# Polarfire SoC register map
Vendor: Microchip; File version: 1.0
CPU: Microchip PolarFire SoC 1.0, little endian
Registers are 32-bit, read-write, reset 0x0 unless marked. A register's access mark holds for its fields unless they carry their own. Offsets are from the block's base; [hi:lo] are bit positions; lines under a group give offsets from that group; {n}, {i} and the like mark numbered series; 'fields as' and 'values as' point back to an identical list.

## USB — MSS USB 2.0 OTG High-Speed Controller
Base 0x20201000
0x00 FADDR 8-bit reset not defined — Function Address Register (peripheral mode)
  [6:0] FUNC_ADDR — USB function address (0–127)
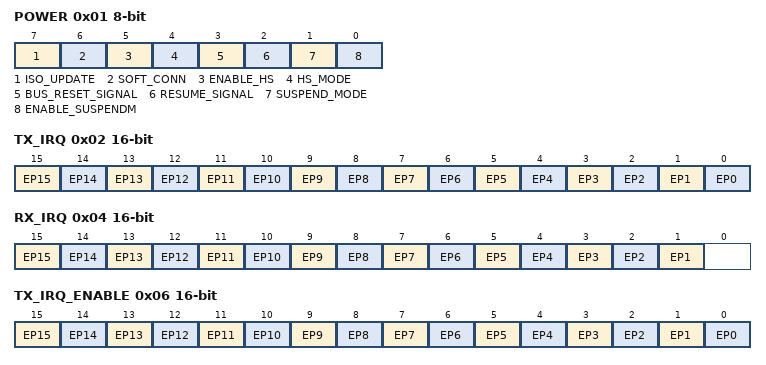
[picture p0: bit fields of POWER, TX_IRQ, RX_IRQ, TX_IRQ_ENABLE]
0x01 POWER 8-bit reset not defined — Power Management and High-Speed Control Register
  [7] ISO_UPDATE — Isochronous update: wait for SOF before sending (peripheral)
  [6] SOFT_CONN — Soft connect / disconnect control (peripheral mode)
  [5] ENABLE_HS — Enable high-speed negotiation during reset
  [4] HS_MODE ro — High-speed mode negotiated and active (read-only)
  [3] BUS_RESET_SIGNAL — USB bus reset signalling active (read-only in device mode)
  [2] RESUME_SIGNAL — Drive resume signalling on the bus
  [1] SUSPEND_MODE ro — USB suspend mode active (read-only)
  [0] ENABLE_SUSPENDM — Enable SuspendM signal output
0x02 TX_IRQ 16-bit ro reset not defined — TX Endpoint Interrupt Status Register (read-clears)
  [n] EP{n} (n=1..15) — TX EP{n} interrupt pending
  [0] EP0 — EP0 interrupt pending
0x04 RX_IRQ 16-bit ro reset not defined — RX Endpoint Interrupt Status Register (read-clears; bit 0 unused)
  [n] EP{n} (n=1..15) — RX EP{n} interrupt pending
0x06 TX_IRQ_ENABLE 16-bit reset not defined — TX Endpoint Interrupt Enable Register
  [n] EP{n} (n=1..15) — TX EP{n} interrupt enable
  [0] EP0 — EP0 / control endpoint interrupt enable
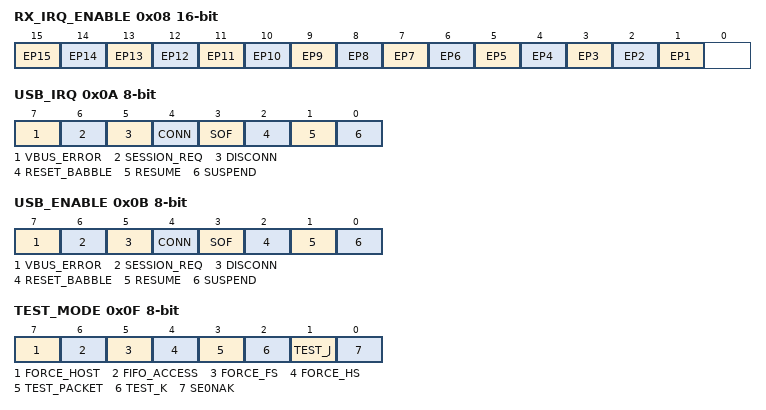
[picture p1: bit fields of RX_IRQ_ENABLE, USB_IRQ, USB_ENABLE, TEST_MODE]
0x08 RX_IRQ_ENABLE 16-bit reset not defined — RX Endpoint Interrupt Enable Register
  [n] EP{n} (n=1..15) — RX EP{n} interrupt enable
0x0A USB_IRQ 8-bit ro reset not defined — USB Common Interrupt Status Register
  [7] VBUS_ERROR — VBUS error (OTG)
  [6] SESSION_REQ — Session-request protocol event (OTG)
  [5] DISCONN — Device disconnected
  [4] CONN — Device connected (host mode)
  [3] SOF — Start-of-Frame token received / generated
  [2] RESET_BABBLE — Bus reset (device) or babble (host) detected
  [1] RESUME — Resume signalling detected
  [0] SUSPEND — Suspend condition detected
0x0B USB_ENABLE 8-bit reset not defined — USB Common Interrupt Enable Register
  [7] VBUS_ERROR — VBUS error interrupt enable
  [6] SESSION_REQ — Session-request interrupt enable
  [5] DISCONN — Disconnect interrupt enable
  [4] CONN — Connect interrupt enable
  [3] SOF — SOF interrupt enable
  [2] RESET_BABBLE — Reset/babble interrupt enable
  [1] RESUME — Resume interrupt enable
  [0] SUSPEND — Suspend interrupt enable
0x0C FRAME 16-bit ro reset not defined — USB Frame Number Register (read-only)
  [10:0] FRAME_NUM — Current USB SOF frame number (0–2047)
0x0E INDEX 8-bit reset not defined — Endpoint Index Register — selects which endpoint CSRs appear at 0x010–0x01F
  [3:0] ENDPOINT_INDEX — Active endpoint number (0–15) for indexed CSR window
0x0F TEST_MODE 8-bit reset not defined — USB Test Mode Control Register
  [7] FORCE_HOST — Force host mode
  [6] FIFO_ACCESS — Enable FIFO access mode (self-clearing)
  [5] FORCE_FS — Force full-speed operation
  [4] FORCE_HS — Force high-speed operation
  [3] TEST_PACKET — Transmit test packet
  [2] TEST_K — Force HS Test_K state
  [1] TEST_J — Force HS Test_J state
  [0] SE0NAK — Force SE0/NAK test
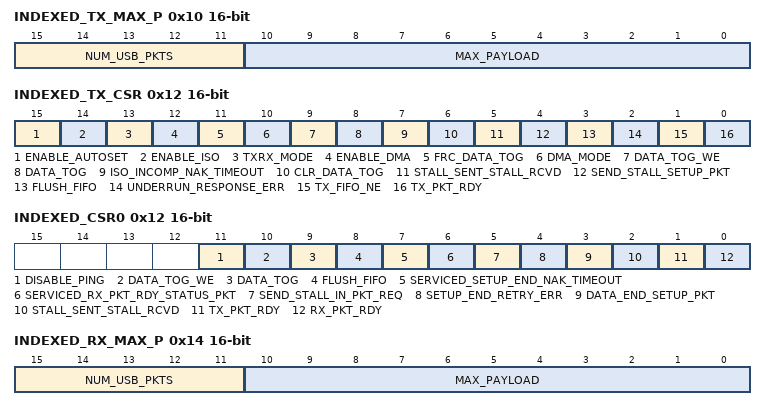
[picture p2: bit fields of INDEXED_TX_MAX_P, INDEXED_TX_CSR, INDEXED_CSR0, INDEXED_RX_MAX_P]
0x10 INDEXED_TX_MAX_P 16-bit reset not defined — Indexed TX Maximum Packet Size (endpoint selected by INDEX)
  [15:11] NUM_USB_PKTS — High-bandwidth packets per micro-frame minus 1 (bits[15:11])
  [10:0] MAX_PAYLOAD — Maximum TX packet payload in bytes (bits[10:0])
0x12 INDEXED_TX_CSR 16-bit reset not defined — Indexed TX Control/Status Register — EPN view (N>0). Upper byte (TxCSRH) carries DMA and mode control. Bit semantics differ between device and host mode.
  [15] ENABLE_AUTOSET — Auto-set TxPktRdy when FIFO full
  [14] ENABLE_ISO — Isochronous mode enable (device only)
  [13] TXRX_MODE — Direction mode: 1=TX only when endpoint is bidirectional
  [12] ENABLE_DMA — Enable DMA request for this TX endpoint
  [11] FRC_DATA_TOG — Force data toggle (used for bulk transactions)
  [10] DMA_MODE — DMA request mode: 0=mode0, 1=mode1
  [9] DATA_TOG_WE — Enable write to DATA_TOG bit (host only, self-clearing)
  [8] DATA_TOG ro — Current TX data toggle value (host only, read-only)
  [7] ISO_INCOMP_NAK_TIMEOUT — Incomplete ISO TX (device) / NAK timeout (host)
  [6] CLR_DATA_TOG — Reset TX data toggle to DATA0
  [5] STALL_SENT_STALL_RCVD — STALL handshake sent (device) / STALL received (host)
  [4] SEND_STALL_SETUP_PKT — Issue STALL handshake (device) / send SETUP token (host)
  [3] FLUSH_FIFO — Flush TX FIFO (self-clearing)
  [2] UNDERRUN_RESPONSE_ERR — Underrun error (device) / no response error (host)
  [1] TX_FIFO_NE ro — TX FIFO not empty (read-only)
  [0] TX_PKT_RDY — Set to indicate TX FIFO loaded; cleared by hardware after transmission
0x12 INDEXED_CSR0 16-bit reset not defined (alternate view of INDEXED_TX_CSR) — Indexed EP0 Control/Status Register — EP0 view only (INDEX=0). Overlaps INDEXED_TX_CSR; bit definitions differ completely.
  [11] DISABLE_PING — Disable PING token generation (host only)
  [10] DATA_TOG_WE — Enable write to DATA_TOG (host only, self-clearing)
  [9] DATA_TOG — Data toggle value (host only)
  [8] FLUSH_FIFO — Flush EP0 FIFO (self-clearing)
  [7] SERVICED_SETUP_END_NAK_TIMEOUT — ServicedSetupEnd (device) / NAK timeout (host)
  [6] SERVICED_RX_PKT_RDY_STATUS_PKT — ServicedRxPktRdy (device) / status packet (host)
  [5] SEND_STALL_IN_PKT_REQ — Issue STALL (device) / IN packet request (host)
  [4] SETUP_END_RETRY_ERR ro — Setup end condition (device, read-only) / retry error (host)
  [3] DATA_END_SETUP_PKT — Signal data end (device) / SETUP packet (host)
  [2] STALL_SENT_STALL_RCVD ro — STALL sent (device) / STALL received (host)
  [1] TX_PKT_RDY — Data packet loaded in EP0 TX FIFO (device/host)
  [0] RX_PKT_RDY ro — Data packet received in EP0 RX FIFO (device) / RX ready (host)
0x14 INDEXED_RX_MAX_P 16-bit reset not defined — Indexed RX Maximum Packet Size (endpoint selected by INDEX)
  [15:11] NUM_USB_PKTS — High-bandwidth packets per micro-frame minus 1 (bits[15:11])
  [10:0] MAX_PAYLOAD — Maximum RX packet payload in bytes (bits[10:0])
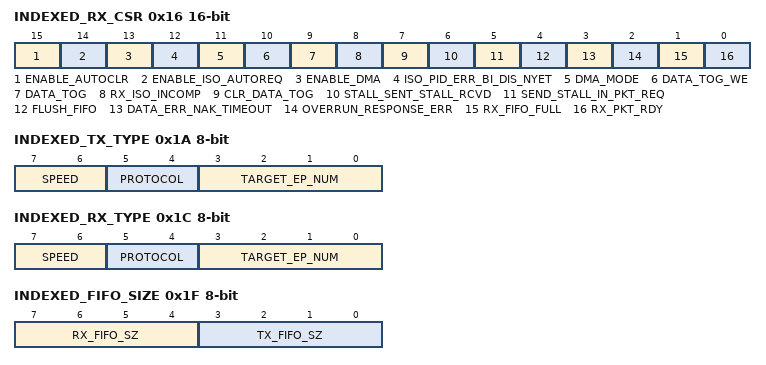
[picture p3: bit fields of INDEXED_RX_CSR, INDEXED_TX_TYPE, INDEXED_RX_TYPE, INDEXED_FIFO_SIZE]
0x16 INDEXED_RX_CSR 16-bit reset not defined — Indexed RX Control/Status Register — EPN view (N>0). Upper byte (RxCSRH) carries DMA, ISO and mode bits. Bit semantics differ between device and host mode.
  [15] ENABLE_AUTOCLR — Auto-clear RxPktRdy when FIFO drained
  [14] ENABLE_ISO_AUTOREQ — ISO mode enable (device) / auto-request IN (host)
  [13] ENABLE_DMA — Enable DMA request for this RX endpoint
  [12] ISO_PID_ERR_BI_DIS_NYET — ISO PID error (device) / disable NYET handshake (host)
  [11] DMA_MODE — DMA request mode: 0=mode0, 1=mode1
  [10] DATA_TOG_WE — Enable write to DATA_TOG (host only)
  [9] DATA_TOG ro — Current RX data toggle (host only, read-only)
  [8] RX_ISO_INCOMP ro — Incomplete ISO RX in this frame
  [7] CLR_DATA_TOG — Reset RX data toggle to DATA0
  [6] STALL_SENT_STALL_RCVD — STALL sent (device) / STALL received (host)
  [5] SEND_STALL_IN_PKT_REQ — Issue STALL (device) / IN packet request (host)
  [4] FLUSH_FIFO — Flush RX FIFO (self-clearing)
  [3] DATA_ERR_NAK_TIMEOUT — Data CRC/bit-stuff error (device) / NAK timeout (host)
  [2] OVERRUN_RESPONSE_ERR — Overrun (device) / no response error (host)
  [1] RX_FIFO_FULL ro — RX FIFO full (read-only)
  [0] RX_PKT_RDY ro — Data packet available in RX FIFO (cleared by software)
0x18 INDEXED_RX_COUNT 16-bit ro reset not defined — Indexed RX Byte Count Register (COUNT0 for EP0; read-only)
  [13:0] COUNT — Number of bytes in RX FIFO (EP0: max 64 / EPN: up to 16383)
0x1A INDEXED_TX_TYPE 8-bit reset not defined — Indexed TX Type Register — target EP, protocol, speed (host mode; TYPE0 for EP0)
  [7:6] SPEED — Target device speed: 00=same as bus, 01=High, 10=Full, 11=Low
    0=SAME_AS_BUS; 1=HIGH_SPEED; 2=FULL_SPEED; 3=LOW_SPEED
  [5:4] PROTOCOL — Transfer type: 00=Control, 01=Isoch, 10=Bulk, 11=Interrupt
    0=CONTROL; 1=ISOCHRONOUS; 2=BULK; 3=INTERRUPT
  [3:0] TARGET_EP_NUM — Target endpoint number on the remote device
0x1B INDEXED_TX_INTERVAL 8-bit reset not defined — Indexed TX Polling Interval / NAK Limit (host; NAK_LIMIT0 for EP0)
  [7:0] INTERVAL — Polling interval (interrupt/ISO) or NAK retry limit (bulk/control)
0x1C INDEXED_RX_TYPE 8-bit reset not defined — Indexed RX Type Register — target EP, protocol, speed (host mode)
  fields as INDEXED_TX_TYPE
0x1D INDEXED_RX_INTERVAL 8-bit reset not defined — Indexed RX Polling Interval / NAK Limit (host mode)
  [7:0] INTERVAL — Polling interval or NAK retry limit
0x1F INDEXED_FIFO_SIZE 8-bit ro reset not defined — Indexed FIFO Size / Config Data Register (read-only)
  [7:4] RX_FIFO_SZ — RX FIFO size encoding [7:4]
  [3:0] TX_FIFO_SZ — TX FIFO size encoding [3:0]
{0x20+4i} FIFO[{i}] (i=0..15) reset not defined — Endpoint {i} FIFO Data Port (32-bit access; 8- and 16-bit accesses also valid)
  [31:0] DATA — FIFO data word
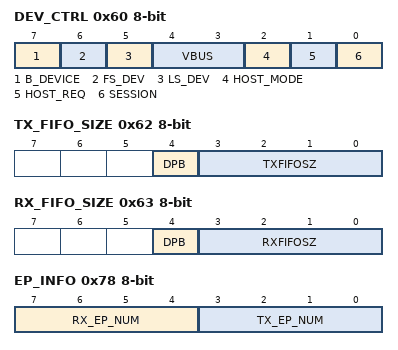
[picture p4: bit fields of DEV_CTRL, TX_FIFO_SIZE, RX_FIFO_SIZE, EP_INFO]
0x60 DEV_CTRL 8-bit reset not defined — OTG Device Control Register
  [7] B_DEVICE ro — B-device role (read-only)
  [6] FS_DEV ro — Full-speed device connected (host mode, read-only)
  [5] LS_DEV ro — Low-speed device connected (host mode, read-only)
  [4:3] VBUS ro — VBUS voltage level (read-only)
    0=BELOW_SESSION_END (VBUS below session end threshold); 1=ABOVE_SESSION_END (VBUS above session end); 2=ABOVE_AVALID (VBUS above AValid); 3=ABOVE_VBUS_VALID (VBUS above VbusValid)
  [2] HOST_MODE ro — Host mode active (read-only)
  [1] HOST_REQ — Host negotiation request (OTG A-device)
  [0] SESSION — Start (write 1) or end (write 0) an OTG session
0x61 MISC 8-bit reset not defined — Miscellaneous Control Register
0x62 TX_FIFO_SIZE 8-bit reset not defined — Dynamic TX FIFO Size Register (indexed endpoint)
  [4] DPB — Double-packet buffering enable
  [3:0] TXFIFOSZ — TX FIFO size: 0=8B,1=16B,2=32B,3=64B,4=128B,5=256B,6=512B,7=1024B,8=2048B,9=4096B
0x63 RX_FIFO_SIZE 8-bit reset not defined — Dynamic RX FIFO Size Register (indexed endpoint)
  [4] DPB — Double-packet buffering enable
  [3:0] RXFIFOSZ — RX FIFO size (same encoding as TX_FIFO_SIZE.TXFIFOSZ)
0x64 TX_FIFO_ADDR 16-bit reset not defined — Dynamic TX FIFO Start Address Register (8-byte units)
  [12:0] ADDR — Start address of TX FIFO allocation in 8-byte units
0x66 RX_FIFO_ADDR 16-bit reset not defined — Dynamic RX FIFO Start Address Register (8-byte units)
  [12:0] ADDR — Start address of RX FIFO allocation in 8-byte units
0x68 VBUS_CSR reset not defined — VBUS Control and Status Register
0x6C HW_VERSION 16-bit ro reset not defined — Hardware Version Register (read-only)
0x70 ULPI_VBUS_CTRL 8-bit reset not defined — ULPI VBUS Control Register
0x71 ULPI_CARKIT_CTRL 8-bit reset not defined — ULPI Carkit Control Register
0x72 ULPI_IRQ_MASK 8-bit reset not defined — ULPI Interrupt Mask Register
0x73 ULPI_IRQ_SRC 8-bit ro reset not defined — ULPI Interrupt Source Register (read-only)
0x74 ULPI_DATA_REG 8-bit reset not defined — ULPI Data Register
0x75 ULPI_ADDR_REG 8-bit reset not defined — ULPI Address Register
0x76 ULPI_CTRL_REG 8-bit reset not defined — ULPI Control Register
0x77 ULPI_RAW_DATA 8-bit ro reset not defined — ULPI Raw Data Register (read-only)
0x78 EP_INFO 8-bit ro reset not defined — Endpoint Information Register (read-only)
  [7:4] RX_EP_NUM — Number of RX endpoints implemented (bits[7:4])
  [3:0] TX_EP_NUM — Number of TX endpoints implemented (bits[3:0])
0x79 RAM_INFO 8-bit ro reset not defined — FIFO RAM Size Information Register (read-only)
0x7A LINK_INFO 8-bit ro reset not defined — Link Layer Timing Information Register (read-only)
0x7B VP_LEN 8-bit reset not defined — VBUS Pulsing Length Register
0x7C HS_EOF1 8-bit reset not defined — High-Speed End-of-Frame Timing Register 1
0x7D FS_EOF1 8-bit reset not defined — Full-Speed End-of-Frame Timing Register 1
0x7E LS_EOF1 8-bit reset not defined — Low-Speed End-of-Frame Timing Register 1
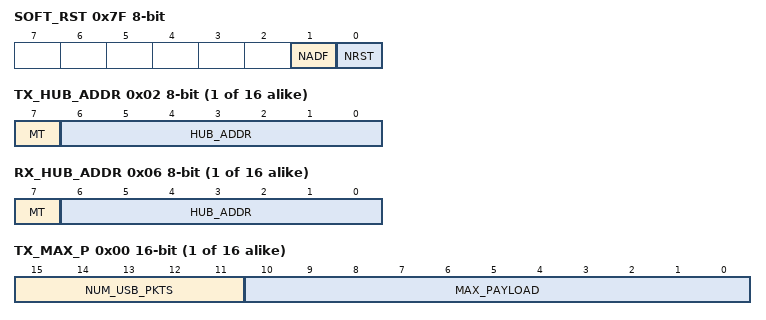
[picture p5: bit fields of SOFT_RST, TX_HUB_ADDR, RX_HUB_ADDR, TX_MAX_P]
0x7F SOFT_RST 8-bit reset not defined — Soft Reset Control Register
  [1] NADF — Assert NADFn reset (bit 1)
  [0] NRST — Assert NRSTn reset (bit 0)
{0x80+8i} TAR[{i}] (i=0..15) group — Target Address / Hub Routing Registers for endpoint {i}
  0x00 TX_FUNC_ADDR 8-bit reset not defined — TX target device function address
    [6:0] ADDR — Target function address (0–127)
  0x02 TX_HUB_ADDR 8-bit reset not defined — TX hub address (TT routing for FS/LS behind HS hub)
    [7] MT — Multi-TT hub flag (bit 7)
    [6:0] HUB_ADDR — Hub function address (bits[6:0])
  0x03 TX_HUB_PORT 8-bit reset not defined — TX hub port number
    [6:0] PORT — Hub port number (0–127)
  0x04 RX_FUNC_ADDR 8-bit reset not defined — RX target device function address
    [6:0] ADDR — Target function address (0–127)
  0x06 RX_HUB_ADDR 8-bit reset not defined — RX hub address
    fields as TAR[0].TX_HUB_ADDR
  0x07 RX_HUB_PORT 8-bit reset not defined — RX hub port number
    [6:0] PORT — Hub port number (0–127)
{0x100+0x10*i} ENDPOINT[{i}] (i=0..15) group — Non-indexed Control and Status Registers for endpoint {i}
  0x00 TX_MAX_P 16-bit reset not defined — TX Maximum Packet Size
    [15:11] NUM_USB_PKTS — High-bandwidth packets per micro-frame minus 1 (bits[15:11])
    [10:0] MAX_PAYLOAD — Maximum TX payload bytes (bits[10:0])
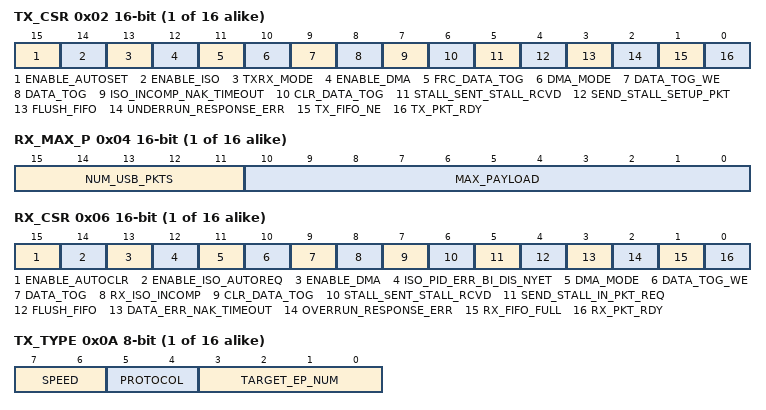
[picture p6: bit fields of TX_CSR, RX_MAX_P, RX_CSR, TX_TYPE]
  0x02 TX_CSR 16-bit reset not defined — TX Control and Status Register (TxCSRL[7:0] + TxCSRH[15:8])
    [15] ENABLE_AUTOSET — Auto-set TxPktRdy when FIFO reaches MaxP
    [14] ENABLE_ISO — Isochronous mode (device only)
    [13] TXRX_MODE — TX/RX direction mode
    [12] ENABLE_DMA — Enable DMA for TX endpoint
    [11] FRC_DATA_TOG — Force data toggle
    [10] DMA_MODE — DMA mode: 0=mode0, 1=mode1
    [9] DATA_TOG_WE — Write enable for DATA_TOG (host only)
    [8] DATA_TOG ro — TX data toggle (host only, read-only)
    [7] ISO_INCOMP_NAK_TIMEOUT — Incomplete ISO TX (device) / NAK timeout (host)
    [6] CLR_DATA_TOG — Reset TX data toggle to DATA0
    [5] STALL_SENT_STALL_RCVD — STALL sent (device) / STALL received (host)
    [4] SEND_STALL_SETUP_PKT — Issue STALL (device) / send SETUP token (host)
    [3] FLUSH_FIFO — Flush TX FIFO (self-clearing)
    [2] UNDERRUN_RESPONSE_ERR — Underrun (device) / no-response error (host)
    [1] TX_FIFO_NE ro — TX FIFO not empty (read-only)
    [0] TX_PKT_RDY — TX FIFO loaded; hardware clears after transmit
  0x04 RX_MAX_P 16-bit reset not defined — RX Maximum Packet Size
    [15:11] NUM_USB_PKTS — High-bandwidth packets per micro-frame minus 1 (bits[15:11])
    [10:0] MAX_PAYLOAD — Maximum RX payload bytes (bits[10:0])
  0x06 RX_CSR 16-bit reset not defined — RX Control and Status Register (RxCSRL[7:0] + RxCSRH[15:8])
    [15] ENABLE_AUTOCLR — Auto-clear RxPktRdy when FIFO drained to zero
    [14] ENABLE_ISO_AUTOREQ — ISO mode (device) / auto-request IN (host)
    [13] ENABLE_DMA — Enable DMA for RX endpoint
    [12] ISO_PID_ERR_BI_DIS_NYET — ISO PID error (device) / disable NYET (host)
    [11] DMA_MODE — DMA mode: 0=mode0, 1=mode1
    [10] DATA_TOG_WE — Write enable for DATA_TOG (host only)
    [9] DATA_TOG ro — RX data toggle (host only, read-only)
    [8] RX_ISO_INCOMP ro — Incomplete ISO RX (read-only)
    [7] CLR_DATA_TOG — Reset RX data toggle to DATA0
    [6] STALL_SENT_STALL_RCVD — STALL sent (device) / STALL received (host)
    [5] SEND_STALL_IN_PKT_REQ — Issue STALL (device) / IN packet request (host)
    [4] FLUSH_FIFO — Flush RX FIFO (self-clearing)
    [3] DATA_ERR_NAK_TIMEOUT — Data error (device) / NAK timeout (host)
    [2] OVERRUN_RESPONSE_ERR — Overrun (device) / no-response error (host)
    [1] RX_FIFO_FULL ro — RX FIFO full (read-only)
    [0] RX_PKT_RDY ro — Packet in RX FIFO; cleared by software after reading
  0x08 RX_COUNT 16-bit ro reset not defined — Number of bytes available in RX FIFO (read-only)
    [13:0] COUNT — Received byte count
  0x0A TX_TYPE 8-bit reset not defined — TX Type Register — target EP, protocol, speed (host mode)
    [7:6] SPEED — 00=same, 01=High, 10=Full, 11=Low
    [5:4] PROTOCOL — 00=Control, 01=Isoch, 10=Bulk, 11=Interrupt
    [3:0] TARGET_EP_NUM — Target endpoint number (bits[3:0])
  0x0B TX_INTERVAL 8-bit reset not defined — TX Polling Interval / NAK Limit (host mode)
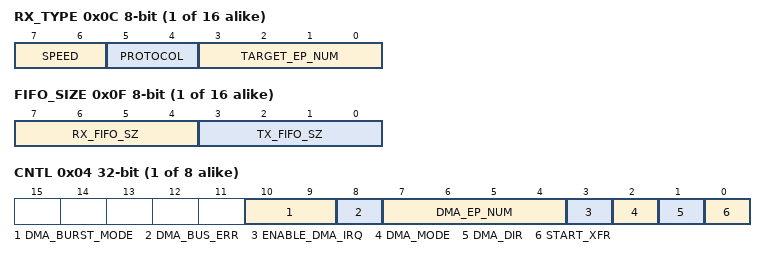
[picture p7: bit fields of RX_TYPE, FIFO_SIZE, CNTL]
  0x0C RX_TYPE 8-bit reset not defined — RX Type Register — target EP, protocol, speed (host mode)
    fields as ENDPOINT[0].TX_TYPE
  0x0D RX_INTERVAL 8-bit reset not defined — RX Polling Interval / NAK Limit (host mode)
  0x0F FIFO_SIZE 8-bit ro reset not defined — TX/RX FIFO Size Encoding Register (read-only)
    [7:4] RX_FIFO_SZ — RX FIFO size encoding (bits[7:4])
    [3:0] TX_FIFO_SZ — TX FIFO size encoding (bits[3:0])
{0x200+0x10*i} DMA_CHANNEL[{i}] (i=0..7) group — DMA Channel {i} Registers
  0x00 IRQ reset not defined — DMA Channel Interrupt Status Register
    [0] DMA_IRQ — DMA transfer complete; write 0 to clear
  0x04 CNTL reset not defined — DMA Channel Control Register
    [10:9] DMA_BURST_MODE — AHB burst size: 00=unspecified, 01=INCR4, 10=INCR8, 11=INCR16
      0=UNSPECIFIED; 1=INCR4; 2=INCR8; 3=INCR16
    [8] DMA_BUS_ERR ro — AHB bus error flag (read-only; cleared by START_XFR)
    [7:4] DMA_EP_NUM — Endpoint associated with this DMA channel (bits[7:4])
    [3] ENABLE_DMA_IRQ — Enable DMA completion interrupt
    [2] DMA_MODE — DMA mode: 0=mode0 (single packet), 1=mode1 (multi-packet)
    [1] DMA_DIR — Direction: 0=RX (write to memory), 1=TX (read from memory)
    [0] START_XFR — Start DMA transfer (self-clearing)
  0x08 ADDR reset not defined — DMA Channel Transfer Start Address Register
  0x0C COUNT reset not defined — DMA Channel Transfer Byte Count Register
{0x300+4i} RQ_PKT_CNT[{i}] (i=0..15) reset not defined — Endpoint {i} Requested Packet Count Register (DMA mode 1)
  [15:0] PKT_COUNT — Number of bulk packets to transfer via DMA mode 1 (bits[15:0])
0x340 RX_DPBUF_DIS 16-bit reset not defined — RX Double-Packet Buffer Disable Register (bit N disables double-buffering on RX endpoint N; bit 0 unused)
0x342 TX_DPBUF_DIS 16-bit reset not defined — TX Double-Packet Buffer Disable Register (bit N disables double-buffering on TX endpoint N; bit 0 unused)
0x344 C_T_UCH 16-bit reset not defined — Chirp Timeout (UCH) Value Register
0x346 C_T_HHSRTN 16-bit reset not defined — Host High-Speed Return (HHSRTN) Timing Register
0x348 C_T_HSBT 16-bit reset not defined — High-Speed Bus Turnaround (HSBT) Timing Register
